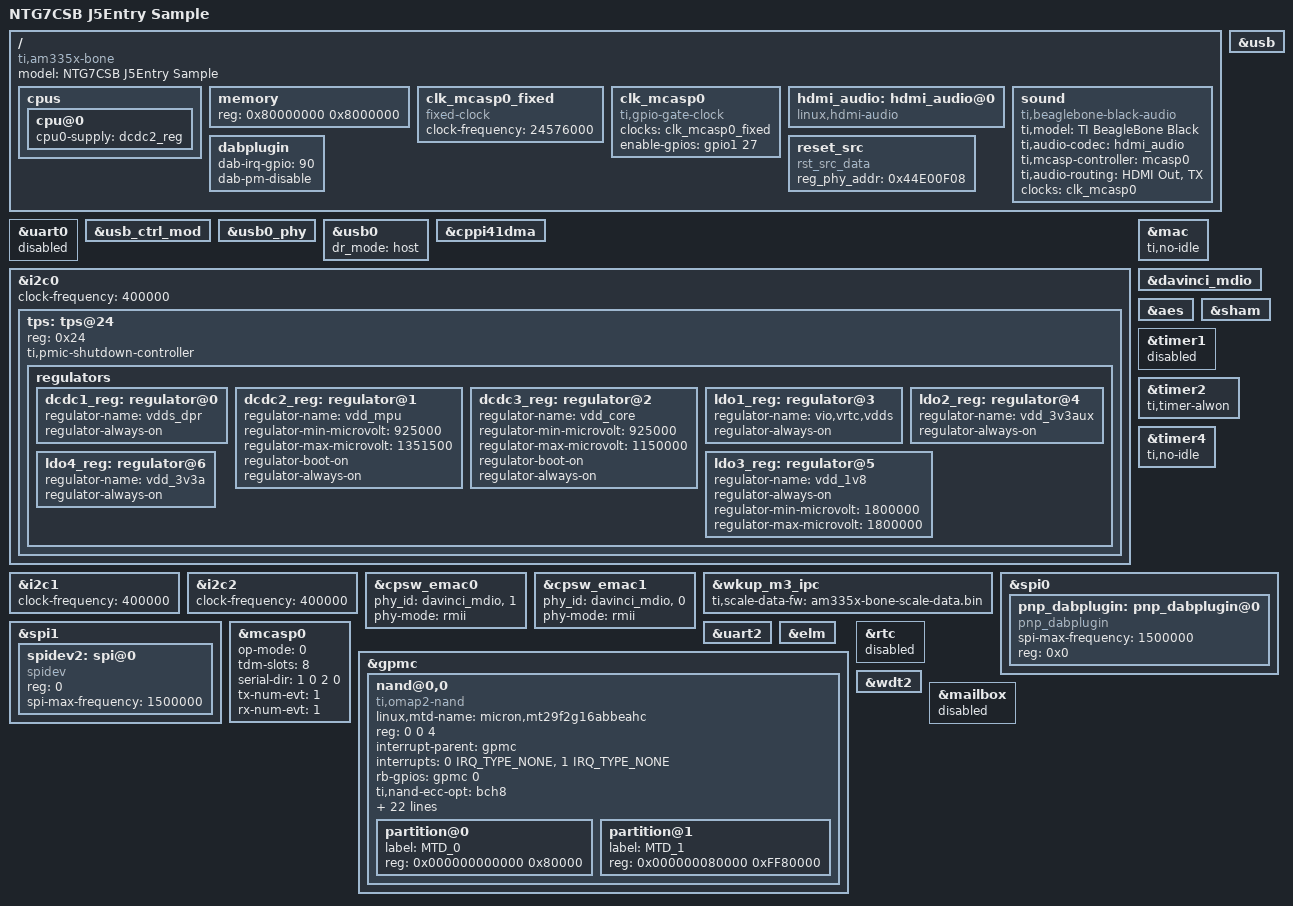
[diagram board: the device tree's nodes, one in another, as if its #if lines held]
/*
 * Copyright (C) 2012 Texas Instruments Incorporated - http://www.ti.com/
 *
 * This program is free software; you can redistribute it and/or modify
 * it under the terms of the GNU General Public License version 2 as
 * published by the Free Software Foundation.
 */
/dts-v1/;

#include "am33xx.dtsi"
#include <dt-bindings/emlinux/emlinux.h>
#include <dt-bindings/interrupt-controller/irq.h>

/ {
	model = "NTG7CSB J5Entry Sample";
	compatible = "ti,am335x-bone", "ti,am33xx";

	cpus {
		cpu@0 {
			cpu0-supply = <&dcdc2_reg>;
		};
	};

	memory {
		device_type = "memory";
		reg = <0x80000000 0x8000000>; /* 128 MB */
	};
};

&uart0 {
#if NO_CONSOLE
        status = "disabled";
#else
        status = "okay";
#endif
	/delete-property/dmas;		/* Disable DMA for console */
	/delete-property/dma-names;
};

&usb {
	status = "okay";
};

&usb_ctrl_mod {
	status = "okay";
};

&usb0_phy {
	status = "okay";
};

&usb0 {
	status = "okay";
	dr_mode = "host";
};

&cppi41dma  {
	status = "okay";
};

&i2c0 {
	pinctrl-names = "default";
	status = "okay";
	clock-frequency = <400000>;

	tps: tps@24 {
		reg = <0x24>;
	};

};

&i2c1 {
        status = "okay";
        clock-frequency = <400000>;
};

&i2c2 {
	pinctrl-names = "default";

	status = "okay";
	clock-frequency = <400000>;

};

&cpsw_emac0 {
	phy_id = <&davinci_mdio>, <1>;
	phy-mode = "rmii";
};

&cpsw_emac1 {
	phy_id = <&davinci_mdio>, <0>;
	phy-mode = "rmii";
};

&mac {
	/*
	 * Do not allow gating of cpsw clock as workaround
	 * for errata i877. Keeping internal clock disabled
	 * causes the device switching characteristics
	 * to degrade over time and eventually fail to meet
	 * the data manual delay time/skew specs.
	 */
	ti,no-idle;
	status = "okay";
};

&davinci_mdio {
	status = "okay";
};

&aes {
	status = "okay";
};

&sham {
	status = "okay";
};

&wkup_m3_ipc {
	ti,scale-data-fw = "am335x-bone-scale-data.bin";
};

&timer1 {
	status = "disabled";
};

&timer2 {
	ti,timer-alwon;
};

&timer4 {
	ti,no-idle;
};

&spi0 {
        status = "okay";
        pinctrl-names = "default";

	/*Added by Mir Faisal on 18-01-2021*/
	pnp_dabplugin: pnp_dabplugin@0 {
		compatible = "pnp_dabplugin";
                spi-max-frequency = <1500000>;
                reg = <0x0>;
	};

#if 0
#if EMLINUX_KERNEL
	spidev0: spi@0 {
                compatible = "spidev";
                reg = <0>;
                spi-max-frequency = <1500000>;
       };
#else
/*
 * Child node of spi0 is removed as the platform data for spi0
 * node will now be populated from driver: dynamic_spi_node.ko
 * We aren't touching the child node in case of emlinux.
 */
#endif
	spidev1: spi@1 {
		compatible = "spidev";
		reg = <1>;
		spi-max-frequency = <1500000>;
	};
#endif

};

&spi1 {
        status = "okay";
        pinctrl-names = "default";
        
        spidev2: spi@0 {
                compatible = "spidev";
                reg = <0>;
                spi-max-frequency = <1500000>;
       };
       
};

&mcasp0	{
	status = "okay";
	op-mode = <0>;	/* MCASP_IIS_MODE */
	tdm-slots = <8>;
	serial-dir = <	/* 0: INACTIVE, 1: TX, 2: RX */
			1 0 2 0
		>;
	tx-num-evt = <1>;
	rx-num-evt = <1>;
};

/ {
	clk_mcasp0_fixed: clk_mcasp0_fixed {
	      #clock-cells = <0>;
	      compatible = "fixed-clock";
	      clock-frequency = <24576000>;
	};

	clk_mcasp0: clk_mcasp0 {
	      #clock-cells = <0>;
	      compatible = "ti,gpio-gate-clock";
	      clocks = <&clk_mcasp0_fixed>;
	      enable-gpios = <&gpio1 27 0>; /* BeagleBone Black Clk enable on GPIO1_27 */
	};

	hdmi_audio: hdmi_audio@0 {
	       compatible = "linux,hdmi-audio";
	       status = "okay";
	};

	sound {
		compatible = "ti,beaglebone-black-audio";
		ti,model = "TI BeagleBone Black";
		ti,audio-codec = <&hdmi_audio>;
		ti,mcasp-controller = <&mcasp0>;
		ti,audio-routing =
			"HDMI Out",	"TX";
		clocks = <&clk_mcasp0>;
		clock-names = "mclk";
	};

	dabplugin {
		/*dab-cs-gpio = <5>;*/
		dab-irq-gpio = <90>;
		/*dab-cs-pinmux = <0x44e1095c 0x2F>;*/
		dab-pm-disable;
	};
};

&uart2 {
	status = "okay";
	pinctrl-names = "default";
};

&elm {
        status = "okay";
};

&gpmc {
	status = "okay";
	pinctrl-names = "default";
	ranges = <0 0 0x08000000 0x10000000>;   /* CS0: 256MB for NAND */
	nand@0,0 {
		compatible = "ti,omap2-nand";
		linux,mtd-name= "micron,mt29f2g16abbeahc";
		reg = <0 0 4>; /* CS0, offset 0, IO size 4 */
		interrupt-parent = <&gpmc>;
		interrupts = <0 IRQ_TYPE_NONE>, /* fifoevent */
			     <1 IRQ_TYPE_NONE>;	/* termcount */
		rb-gpios = <&gpmc 0 GPIO_ACTIVE_HIGH>; /* gpmc_wait0 */

		ti,nand-ecc-opt = "bch8";
		ti,nand-xfer-type = "prefetch-dma";
		ti,elm-id = <&elm>;
		nand-bus-width = <16>;
		gpmc,device-width = <2>;

		gpmc,clk-activation-ns = <0>;
		gpmc,wait-monitoring-ns = <0>;
		gpmc,cs-rd-off-ns = <60>;
		gpmc,cs-wr-off-ns = <50>;
		gpmc,adv-rd-off-ns = <0>;
		gpmc,adv-wr-off-ns = <50>;
		gpmc,oe-on-ns = <0>;
		gpmc,oe-off-ns = <50>;
		gpmc,we-on-ns = <0>;
		gpmc,we-off-ns = <30>;
		gpmc,rd-cycle-ns = <60>;
		gpmc,wr-cycle-ns = <50>;
		gpmc,access-ns = <50>;
		gpmc,page-burst-access-ns = <0>;
		gpmc,bus-turnaround-ns = <50>;
		gpmc,cycle2cycle-delay-ns = <0>;
		gpmc,wr-data-mux-bus-ns = <0>;
		gpmc,wr-access-ns = <0>;

		#address-cells = <1>;
		#size-cells = <1>;

		/*nand partition*/

		partition@0 {
			label = "MTD_0";
			reg = <0x000000000000 0x80000>;
		};
		partition@1 {
			label = "MTD_1";
			reg = <0x000000080000 0xFF80000>;
		};
	};
};

&rtc {
	status = "disabled";
};

&wdt2 {
	status = "okay";
};

&mailbox {
	status = "disabled";
};

&tps {
	/*
	 * Configure pmic to enter OFF-state instead of SLEEP-state ("RTC-only
	 * mode") at poweroff.  Most BeagleBone versions do not support RTC-only
	 * mode and risk hardware damage if this mode is entered.
	 *
	 * For details, see linux-omap mailing list May 2015 thread
	 *	[PATCH] ARM: dts: am335x-bone* enable pmic-shutdown-controller
	 * In particular, messages:
	 *	http://www.spinics.net/lists/linux-omap/msg118585.html
	 *	http://www.spinics.net/lists/linux-omap/msg118615.html
	 *
	 * You can override this later with
	 *	&tps {  /delete-property/ ti,pmic-shutdown-controller;  }
	 * if you want to use RTC-only mode and made sure you are not affected
	 * by the hardware problems. (Tip: double-check by performing a current
	 * measurement after shutdown: it should be less than 1 mA.)
	 */
	ti,pmic-shutdown-controller;

	regulators {
		dcdc1_reg: regulator@0 {
			regulator-name = "vdds_dpr";
			regulator-always-on;
		};

		dcdc2_reg: regulator@1 {
			/* VDD_MPU voltage limits 0.95V - 1.26V with +/-4% tolerance */
			regulator-name = "vdd_mpu";
			regulator-min-microvolt = <925000>;
			regulator-max-microvolt = <1351500>;
			regulator-boot-on;
			regulator-always-on;
		};

		dcdc3_reg: regulator@2 {
			/* VDD_CORE voltage limits 0.95V - 1.1V with +/-4% tolerance */
			regulator-name = "vdd_core";
			regulator-min-microvolt = <925000>;
			regulator-max-microvolt = <1150000>;
			regulator-boot-on;
			regulator-always-on;
		};

		ldo1_reg: regulator@3 {
			regulator-name = "vio,vrtc,vdds";
			regulator-always-on;
		};

		ldo2_reg: regulator@4 {
			regulator-name = "vdd_3v3aux";
			regulator-always-on;
		};

		ldo3_reg: regulator@5 {
			regulator-name = "vdd_1v8";
			regulator-always-on;
		};

		ldo4_reg: regulator@6 {
			regulator-name = "vdd_3v3a";
			regulator-always-on;
		};
	};
};


&ldo3_reg {
	regulator-min-microvolt = <1800000>;
	regulator-max-microvolt = <1800000>;
	regulator-always-on;
};

/ {
	reset_src {
	compatible = "rst_src_data";
	reg_phy_addr = <0x44E00F08>;
	};
};
